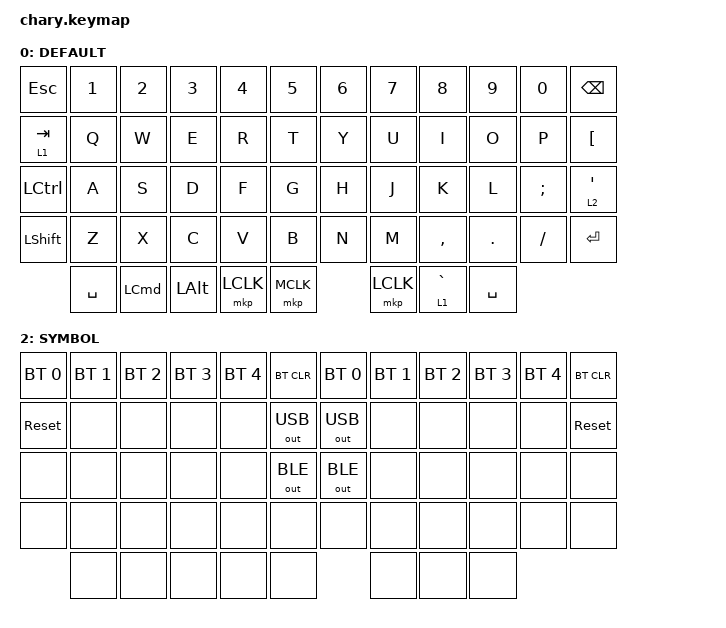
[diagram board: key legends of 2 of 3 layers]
#include <dt-bindings/zmk/mouse.h>
#include <behaviors.dtsi>
#include <dt-bindings/zmk/bt.h>
#include <dt-bindings/zmk/keys.h>
#include <dt-bindings/zmk/outputs.h>
#include <dt-bindings/zmk/pointing.h>

#define DEFAULT 0
#define NUMBER  1
#define SYMBOL  2
#define HOTKEY  3

#define AS(keycode) &as LS(keycode) keycode

/ {
    combos { compatible = "zmk,combos"; };

    keymap {
        compatible = "zmk,keymap";

        default_layer {
            label = "DEFAULT";
            bindings = <
&kp ESCAPE  &kp N1     &kp N2    &kp N3    &kp N4     &kp N5     &kp N6  &kp N7     &kp N8       &kp N9     &kp N0    &kp BACKSPACE
&lt 1 TAB   &kp Q      &kp W     &kp E     &kp R      &kp T      &kp Y   &kp U      &kp I        &kp O      &kp P     &kp LEFT_BRACKET
&kp LCTRL   &kp A      &kp S     &kp D     &kp F      &kp G      &kp H   &kp J      &kp K        &kp L      &kp SEMI  &lt 2 SINGLE_QUOTE
&kp LSHFT   &kp Z      &kp X     &kp C     &kp V      &kp B      &kp N   &kp M      &kp COMMA    &kp DOT    &kp FSLH  &kp ENTER
            &kp SPACE  &kp LCMD  &kp LALT  &mkp LCLK  &mkp MCLK          &mkp LCLK  &lt 1 GRAVE  &kp SPACE
            >;
        };

        number_layer {
            label = "NUMBER";
            bindings = <
&kp F12  &kp F1    &kp F2        &kp F3     &kp F4  &kp F5  &kp F6          &kp F7     &kp F8    &kp F9    &kp F10        &kp F11
&none    &none     &kp UP_ARROW  &none      &none   &none   &none           &none      &none     &none     &kp C_VOL_DN   &kp C_VOL_UP
&trans   &kp LEFT  &kp DOWN      &kp RIGHT  &none   &none   &kp MINUS       &kp EQUAL  &kp LBKT  &kp RBKT  &kp BACKSLASH  &kp RBKT
&trans   &none     &none         &none      &none   &none   &kp UNDERSCORE  &kp PLUS   &kp LBRC  &kp RBRC  &kp PIPE       &kp ENTER
         &trans    &trans        &trans     &none   &none                   &trans
            >;
        };

        symbol_layer {
            label = "SYMBOL";
            bindings = <
&bt BT_SEL 0  &bt BT_SEL 1  &bt BT_SEL 2  &bt BT_SEL 3  &bt BT_SEL 4  &bt BT_CLR    &bt BT_SEL 0  &bt BT_SEL 1  &bt BT_SEL 2  &bt BT_SEL 3  &bt BT_SEL 4  &bt BT_CLR
&sys_reset    &none         &none         &none         &none         &out OUT_USB  &out OUT_USB  &none         &none         &none         &none         &sys_reset
&none         &none         &none         &none         &none         &out OUT_BLE  &out OUT_BLE  &none         &none         &none         &none         &none
&none         &none         &none         &none         &none         &none         &none         &none         &none         &none         &none         &none
              &none         &none         &none         &none         &none                       &none         &none         &none
            >;
        };
    };
};
